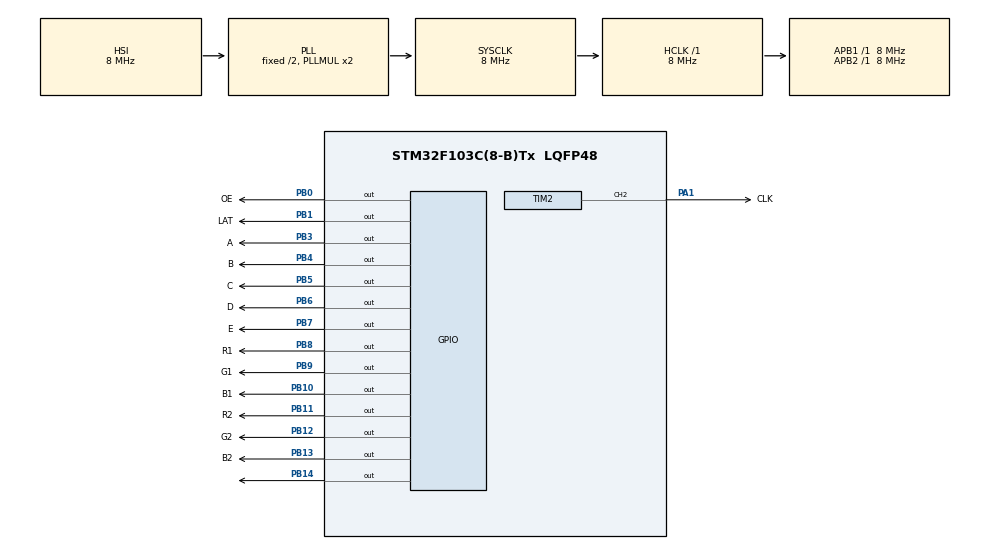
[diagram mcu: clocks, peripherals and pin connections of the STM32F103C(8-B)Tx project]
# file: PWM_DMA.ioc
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Dma.Request0=TIM2_UP
Dma.TIM2_UP.0.Direction=DMA_MEMORY_TO_PERIPH
Dma.TIM2_UP.0.Instance=DMA1_Channel2
Dma.TIM2_UP.0.MemDataAlignment=DMA_MDATAALIGN_HALFWORD
Dma.TIM2_UP.0.MemInc=DMA_MINC_ENABLE
Dma.TIM2_UP.0.Mode=DMA_NORMAL
Dma.TIM2_UP.0.PeriphDataAlignment=DMA_PDATAALIGN_HALFWORD
Dma.TIM2_UP.0.PeriphInc=DMA_PINC_DISABLE
Dma.TIM2_UP.0.Priority=DMA_PRIORITY_LOW
Mcu.Family=STM32F1
Mcu.Name=STM32F103C(8-B)Tx
Mcu.Package=LQFP48
NVIC.DMA1_Channel2_IRQn=true\:0\:0\:false\:false\:true\:false\:true\:true
NVIC.PriorityGroup=NVIC_PRIORITYGROUP_4
PA1.GPIO_Label=CLK
PA1.GPIO_Speed=GPIO_SPEED_FREQ_HIGH
PA1.Signal=S_TIM2_CH2
PA13.Mode=Serial_Wire
PA13.Signal=SYS_JTMS-SWDIO
PA14.Mode=Serial_Wire
PA14.Signal=SYS_JTCK-SWCLK
PB0.GPIO_Label=OE
PB0.GPIO_ModeDefaultOutputPP=GPIO_MODE_OUTPUT_PP
PB0.GPIO_PuPd=GPIO_NOPULL
PB0.GPIO_Speed=GPIO_SPEED_FREQ_HIGH
PB0.PinState=GPIO_PIN_SET
PB0.Signal=GPIO_Output
PB1.GPIO_Label=LAT
PB1.GPIO_ModeDefaultOutputPP=GPIO_MODE_OUTPUT_PP
PB1.GPIO_PuPd=GPIO_NOPULL
PB1.GPIO_Speed=GPIO_SPEED_FREQ_HIGH
PB1.PinState=GPIO_PIN_SET
PB1.Signal=GPIO_Output
PB10.GPIO_Label=B1
PB10.GPIO_ModeDefaultOutputPP=GPIO_MODE_OUTPUT_PP
PB10.GPIO_PuPd=GPIO_NOPULL
PB10.GPIO_Speed=GPIO_SPEED_FREQ_HIGH
PB10.Signal=GPIO_Output
PB11.GPIO_Label=R2
PB11.GPIO_ModeDefaultOutputPP=GPIO_MODE_OUTPUT_PP
PB11.GPIO_PuPd=GPIO_NOPULL
PB11.GPIO_Speed=GPIO_SPEED_FREQ_HIGH
PB11.Signal=GPIO_Output
PB12.GPIO_Label=G2
PB12.GPIO_ModeDefaultOutputPP=GPIO_MODE_OUTPUT_PP
PB12.GPIO_PuPd=GPIO_NOPULL
PB12.GPIO_Speed=GPIO_SPEED_FREQ_HIGH
PB12.Signal=GPIO_Output
PB13.GPIO_Label=B2
PB13.GPIO_ModeDefaultOutputPP=GPIO_MODE_OUTPUT_PP
PB13.GPIO_PuPd=GPIO_NOPULL
PB13.GPIO_Speed=GPIO_SPEED_FREQ_HIGH
PB13.Signal=GPIO_Output
PB14.GPIO_ModeDefaultOutputPP=GPIO_MODE_OUTPUT_PP
PB14.GPIO_PuPd=GPIO_NOPULL
PB14.GPIO_Speed=GPIO_SPEED_FREQ_HIGH
PB14.PinState=GPIO_PIN_SET
PB14.Signal=GPIO_Output
PB3.GPIO_Label=A
PB3.GPIO_ModeDefaultOutputPP=GPIO_MODE_OUTPUT_PP
PB3.GPIO_PuPd=GPIO_NOPULL
PB3.GPIO_Speed=GPIO_SPEED_FREQ_LOW
PB3.Signal=GPIO_Output
PB4.GPIO_Label=B
PB4.GPIO_ModeDefaultOutputPP=GPIO_MODE_OUTPUT_PP
PB4.GPIO_PuPd=GPIO_NOPULL
PB4.GPIO_Speed=GPIO_SPEED_FREQ_LOW
PB4.Signal=GPIO_Output
PB5.GPIO_Label=C
PB5.GPIO_ModeDefaultOutputPP=GPIO_MODE_OUTPUT_PP
PB5.GPIO_PuPd=GPIO_NOPULL
PB5.GPIO_Speed=GPIO_SPEED_FREQ_LOW
PB5.Signal=GPIO_Output
PB6.GPIO_Label=D
PB6.GPIO_ModeDefaultOutputPP=GPIO_MODE_OUTPUT_PP
PB6.GPIO_PuPd=GPIO_NOPULL
PB6.GPIO_Speed=GPIO_SPEED_FREQ_LOW
PB6.Signal=GPIO_Output
PB7.GPIO_Label=E
PB7.GPIO_ModeDefaultOutputPP=GPIO_MODE_OUTPUT_PP
PB7.GPIO_PuPd=GPIO_NOPULL
PB7.GPIO_Speed=GPIO_SPEED_FREQ_LOW
PB7.Signal=GPIO_Output
PB8.GPIO_Label=R1
PB8.GPIO_ModeDefaultOutputPP=GPIO_MODE_OUTPUT_PP
PB8.GPIO_PuPd=GPIO_NOPULL
PB8.GPIO_Speed=GPIO_SPEED_FREQ_HIGH
PB8.Signal=GPIO_Output
PB9.GPIO_Label=G1
PB9.GPIO_ModeDefaultOutputPP=GPIO_MODE_OUTPUT_PP
PB9.GPIO_PuPd=GPIO_NOPULL
PB9.GPIO_Speed=GPIO_SPEED_FREQ_HIGH
PB9.Signal=GPIO_Output
ProjectManager.HeapSize=0x200
ProjectManager.StackSize=0x400
ProjectManager.TargetToolchain=MDK-ARM V5.32
RCC.AHBFreq_Value=8000000
RCC.APB1Freq_Value=8000000
RCC.APB1TimFreq_Value=8000000
RCC.APB2Freq_Value=8000000
RCC.APB2TimFreq_Value=8000000
RCC.HCLKFreq_Value=8000000
RCC.SYSCLKFreq_VALUE=8000000
RCC.SYSCLKSource=RCC_SYSCLKSOURCE_PLLCLK
RCC.USBFreq_Value=8000000
SH.S_TIM2_CH2.0=TIM2_CH2,PWM Generation2 CH2
TIM2.AutoReloadPreload=TIM_AUTORELOAD_PRELOAD_ENABLE
TIM2.Channel-PWM\ Generation2\ CH2=TIM_CHANNEL_2
TIM2.Period=3
TIM2.Prescaler=1
TIM2.Pulse-PWM\ Generation2\ CH2=2
TIM2.TIM_MasterOutputTrigger=TIM_TRGO_UPDATE
VP_TIM2_VS_ClockSourceINT.Mode=Internal
board=custom

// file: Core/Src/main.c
/* USER CODE BEGIN Header */
/**
  ******************************************************************************
  * @file           : main.c
  * @brief          : Main program body
  ******************************************************************************
  * @attention
  *
  * Copyright (c) 2026 STMicroelectronics.
  * All rights reserved.
  *
  * This software is licensed under terms that can be found in the LICENSE file
  * in the root directory of this software component.
  * If no LICENSE file comes with this software, it is provided AS-IS.
  *
  ******************************************************************************
  */
/* USER CODE END Header */
#include "main.h"

/* USER CODE BEGIN Includes */
#include "image.h"
/* USER CODE END Includes */

/* USER CODE BEGIN PD */
#define BUFFER_SIZE (64 * 32)
#define Depth 4
/* USER CODE END PD */

TIM_HandleTypeDef htim2;
DMA_HandleTypeDef hdma_tim2_up;

/* USER CODE BEGIN PV */
//static uint16_t dma_buffer[BUFFER_SIZE*Depth] = { 0 };

/* USER CODE END PV */

void SystemClock_Config(void);
static void MX_GPIO_Init(void);
static void MX_DMA_Init(void);
static void MX_TIM2_Init(void);
/* USER CODE BEGIN PFP */
//static uint16_t dma_buffer[10] = {0x0000, 0xffff,0x0000, 0xffff,0x0000, 0xffff,0x0000, 0xffff,0x0000, 0xffff};
/* USER CODE END PFP */

/* USER CODE BEGIN 0 */
/*DMA全满搬运回调函数*/
void XferCpltCallback(DMA_HandleTypeDef  *hdma){
	if(hdma->Instance == hdma_tim2_up.Instance){
		HAL_DMA_Start_IT(&hdma_tim2_up, (uint32_t)dma_buffer, (uint32_t)&GPIOB->ODR, sizeof(dma_buffer)/sizeof(dma_buffer[0]));
	}
}

/* USER CODE END 0 */

int main(void)
{

  /* USER CODE BEGIN 1 */

	/*CLK波由TIM2 channel2 (PA1)产生*/

  /* USER CODE END 1 */

  /* MCU Configuration--------------------------------------------------------*/

  /* Reset of all peripherals, Initializes the Flash interface and the Systick. */
  HAL_Init();

  /* Configure the system clock */
  SystemClock_Config();

  /* Initialize all configured peripherals */
  MX_GPIO_Init();
  MX_DMA_Init();
  MX_TIM2_Init();
  /* USER CODE BEGIN 2 */

  /* 连接定时器与DMA�? 定时器设置频率，DMA搬运数据
	*  若定时器频率�?1KHz，则DMA�?1ms搬运�?个数据�??*/
	HAL_DMA_RegisterCallback(&hdma_tim2_up, HAL_DMA_XFER_CPLT_CB_ID, XferCpltCallback); //中断注册函数！！！必须
	HAL_DMA_Start_IT(&hdma_tim2_up, (uint32_t)dma_buffer, (uint32_t)&GPIOB->ODR, sizeof(dma_buffer)/sizeof(dma_buffer[0]));
	__HAL_TIM_ENABLE_DMA(&htim2, TIM_DMA_UPDATE);
	HAL_TIM_Base_Start(&htim2);

  HAL_TIM_PWM_Start(&htim2, TIM_CHANNEL_2); //�?启PWM CLK（PA1�?
  /* USER CODE END 2 */

  /* Infinite loop */
  while (1)
  {

  }
}

void SystemClock_Config(void)
{
  RCC_OscInitTypeDef RCC_OscInitStruct = {0};
  RCC_ClkInitTypeDef RCC_ClkInitStruct = {0};

  /** Initializes the RCC Oscillators according to the specified parameters
  * in the RCC_OscInitTypeDef structure.
  */
  RCC_OscInitStruct.OscillatorType = RCC_OSCILLATORTYPE_HSI;
  RCC_OscInitStruct.HSIState = RCC_HSI_ON;
  RCC_OscInitStruct.HSICalibrationValue = RCC_HSICALIBRATION_DEFAULT;
  RCC_OscInitStruct.PLL.PLLState = RCC_PLL_ON;
  RCC_OscInitStruct.PLL.PLLSource = RCC_PLLSOURCE_HSI_DIV2;
  RCC_OscInitStruct.PLL.PLLMUL = RCC_PLL_MUL2;
  if (HAL_RCC_OscConfig(&RCC_OscInitStruct) != HAL_OK)
  {
    Error_Handler();
  }

  /** Initializes the CPU, AHB and APB buses clocks
  */
  RCC_ClkInitStruct.ClockType = RCC_CLOCKTYPE_HCLK|RCC_CLOCKTYPE_SYSCLK
                              |RCC_CLOCKTYPE_PCLK1|RCC_CLOCKTYPE_PCLK2;
  RCC_ClkInitStruct.SYSCLKSource = RCC_SYSCLKSOURCE_PLLCLK;
  RCC_ClkInitStruct.AHBCLKDivider = RCC_SYSCLK_DIV1;
  RCC_ClkInitStruct.APB1CLKDivider = RCC_HCLK_DIV1;
  RCC_ClkInitStruct.APB2CLKDivider = RCC_HCLK_DIV1;

  if (HAL_RCC_ClockConfig(&RCC_ClkInitStruct, FLASH_LATENCY_0) != HAL_OK)
  {
    Error_Handler();
  }
}

static void MX_TIM2_Init(void)
{

  TIM_ClockConfigTypeDef sClockSourceConfig = {0};
  TIM_MasterConfigTypeDef sMasterConfig = {0};
  TIM_OC_InitTypeDef sConfigOC = {0};

  htim2.Instance = TIM2;
  htim2.Init.Prescaler = 1;
  htim2.Init.CounterMode = TIM_COUNTERMODE_UP;
  htim2.Init.Period = 3;
  htim2.Init.ClockDivision = TIM_CLOCKDIVISION_DIV1;
  htim2.Init.AutoReloadPreload = TIM_AUTORELOAD_PRELOAD_ENABLE;
  if (HAL_TIM_Base_Init(&htim2) != HAL_OK)
  {
    Error_Handler();
  }
  sClockSourceConfig.ClockSource = TIM_CLOCKSOURCE_INTERNAL;
  if (HAL_TIM_ConfigClockSource(&htim2, &sClockSourceConfig) != HAL_OK)
  {
    Error_Handler();
  }
  if (HAL_TIM_PWM_Init(&htim2) != HAL_OK)
  {
    Error_Handler();
  }
  sMasterConfig.MasterOutputTrigger = TIM_TRGO_UPDATE;
  sMasterConfig.MasterSlaveMode = TIM_MASTERSLAVEMODE_DISABLE;
  if (HAL_TIMEx_MasterConfigSynchronization(&htim2, &sMasterConfig) != HAL_OK)
  {
    Error_Handler();
  }
  sConfigOC.OCMode = TIM_OCMODE_PWM1;
  sConfigOC.Pulse = 2;
  sConfigOC.OCPolarity = TIM_OCPOLARITY_HIGH;
  sConfigOC.OCFastMode = TIM_OCFAST_DISABLE;
  if (HAL_TIM_PWM_ConfigChannel(&htim2, &sConfigOC, TIM_CHANNEL_2) != HAL_OK)
  {
    Error_Handler();
  }
  HAL_TIM_MspPostInit(&htim2);

}

static void MX_DMA_Init(void)
{

  /* DMA controller clock enable */
  __HAL_RCC_DMA1_CLK_ENABLE();

  /* DMA interrupt init */
  /* DMA1_Channel2_IRQn interrupt configuration */
  HAL_NVIC_SetPriority(DMA1_Channel2_IRQn, 0, 0);
  HAL_NVIC_EnableIRQ(DMA1_Channel2_IRQn);

}

static void MX_GPIO_Init(void)
{
  GPIO_InitTypeDef GPIO_InitStruct = {0};

  /* GPIO Ports Clock Enable */
  __HAL_RCC_GPIOA_CLK_ENABLE();
  __HAL_RCC_GPIOB_CLK_ENABLE();

  /*Configure GPIO pin Output Level */
  HAL_GPIO_WritePin(GPIOB, OE_Pin|LAT_Pin|GPIO_PIN_14, GPIO_PIN_SET);

  /*Configure GPIO pin Output Level */
  HAL_GPIO_WritePin(GPIOB, B1_Pin|R2_Pin|G2_Pin|B2_Pin
                          |A_Pin|B_Pin|C_Pin|D_Pin
                          |E_Pin|R1_Pin|G1_Pin, GPIO_PIN_RESET);

  /*Configure GPIO pins : OE_Pin LAT_Pin B1_Pin R2_Pin
                           G2_Pin B2_Pin PB14 R1_Pin
                           G1_Pin */
  GPIO_InitStruct.Pin = OE_Pin|LAT_Pin|B1_Pin|R2_Pin
                          |G2_Pin|B2_Pin|GPIO_PIN_14|R1_Pin
                          |G1_Pin;
  GPIO_InitStruct.Mode = GPIO_MODE_OUTPUT_PP;
  GPIO_InitStruct.Pull = GPIO_NOPULL;
  GPIO_InitStruct.Speed = GPIO_SPEED_FREQ_HIGH;
  HAL_GPIO_Init(GPIOB, &GPIO_InitStruct);

  /*Configure GPIO pins : A_Pin B_Pin C_Pin D_Pin
                           E_Pin */
  GPIO_InitStruct.Pin = A_Pin|B_Pin|C_Pin|D_Pin
                          |E_Pin;
  GPIO_InitStruct.Mode = GPIO_MODE_OUTPUT_PP;
  GPIO_InitStruct.Pull = GPIO_NOPULL;
  GPIO_InitStruct.Speed = GPIO_SPEED_FREQ_LOW;
  HAL_GPIO_Init(GPIOB, &GPIO_InitStruct);

}

void Error_Handler(void)
{
  __disable_irq();
  while (1)
  {
  }
}
